# Template register map
Vendor: VendorName Co.Ltd; Series: SeriesName; File version: 1.2
CPU: CM0+ r0p1, little endian, no MPU, no FPU, 3 interrupt priority bits
Registers are 32-bit, read-write, no defined reset value unless marked. A register's access mark holds for its fields unless they carry their own. Offsets are from the block's base; lines under a group give offsets from that group; [hi:lo] are bit positions; {n}, {i} and the like mark numbered series; 'fields as' and 'values as' point back to an identical list; <NAME> marks a mode.

## Memory map
0x40000400 GTIM size 0x334 — General Timer
0x40002C00 WWDT size 0xC
0x40003000 IWDT size 0x28
0x40004400 UART2 size 0x38
0x40005400 I2C size 0x2C
0x40010000 SYSCTRL size 0x78 — System Ctrl
0x40012400 ADC size 0x8C
0x40012A00 VC1 size 0x10
0x40012A10 VC2 size 0x10
0x40012A80 LVD size 0xC
0x40012C00 ATIM size 0x5C
0x40013000 SPI size 0x1C
0x40013800 UART1 size 0x38
0x40014800 BTIM1 size 0x20 — Base Timer 1
0x40014900 BTIM2 size 0x20 — Base Timer 2
0x40014A00 BTIM3 size 0x20 — Base Timer 3
0x40014C00 AWT size 0x20
0x40022000 FLASH size 0x2C
0x40022400 RAM size 0x10
0x40023000 CRC size 0x10
0x48000000 GPIOA size 0x64
0x48000400 GPIOB size 0x64
0x48000800 GPIOC size 0x64

## Interrupts
0 WDT (IWDT, WWDT) — Watch Dog Timer Interrupt
1 LVD — Low Voltage Detect Interrupt
3 FLASHRAM (FLASH, RAM) — Flash/RAM Interrupt
4 RCC (SYSCTRL) — RCC Interupt
5 GPIOA — GPIOA Interrupt
6 GPIOB — GPIOB Interrupt
7 GPIOC — GPIOC Interrupt
12 ADC — ADC Interrupt
13 ATIM — Advanced Timer Interrupt
14 VC1 — Voltage Comparator 1 Interrupt
15 VC2 — Voltage Comparator 2 Interrupt
16 GTIM — General Timer Interrupt
20 BTIM1 — Base Timer1 Interrupt
21 BTIM2 — Base Timer2 Interrupt
22 BTIM3 — Base Timer3 Interrupt
23 I2C — I2C Interrupt
25 SPI — SPI Interrupt
27 UART1 — UART1 Interrupt
28 UART2 — UART2 Interrupt
30 AWT — Auto Wakeup Timer Interrupt

## ADC
Base 0x40012400
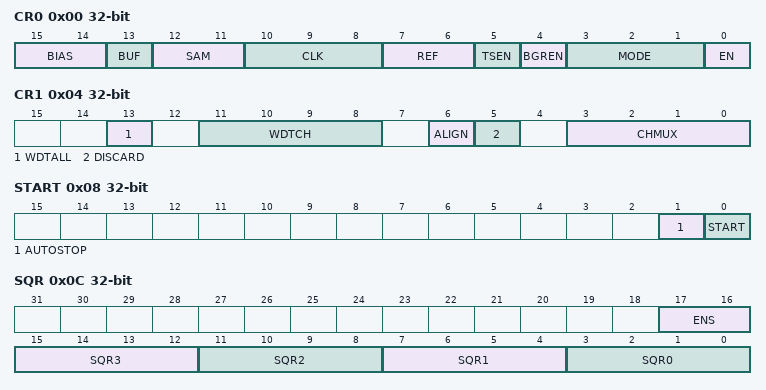
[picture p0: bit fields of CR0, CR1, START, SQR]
0x00 CR0 — Control register0
  [15:14] BIAS, [13] BUF, [12:11] SAM, [10:8] CLK, [7:6] REF, [5] TSEN, [4] BGREN, [3:1] MODE, [0] EN
0x04 CR1 — Control register1
  [13] WDTALL, [11:8] WDTCH, [6] ALIGN, [5] DISCARD, [3:0] CHMUX
0x08 START
  [1] AUTOSTOP, [0] START
0x0C SQR
  [17:16] ENS, [4n+3:4n] SQR{n} (n=0..3)
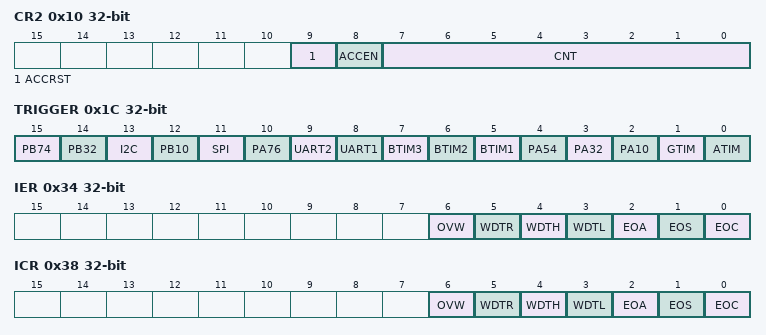
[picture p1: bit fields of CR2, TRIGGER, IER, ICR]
0x10 CR2 — Control register2
  [9] ACCRST, [8] ACCEN, [7:0] CNT
0x14 VTH
  [11:0] VTH
0x18 VTL
  [11:0] VTL
0x1C TRIGGER
  [15] PB74, [14] PB32, [13] I2C, [12] PB10, [11] SPI, [10] PA76, [9] UART2, [8] UART1, [7] BTIM3, [6] BTIM2, [5] BTIM1, [4] PA54, [3] PA32, [2] PA10, [1] GTIM, [0] ATIM
{0x20+4i} RESULT{i} ro (i=0..3)
  [15:0] RESULT
0x30 RESULTACC ro
  [23:0] RESULT
0x34 IER — Interrupt enable register
  [6] OVW, [5] WDTR, [4] WDTH, [3] WDTL, [2] EOA, [1] EOS, [0] EOC
0x38 ICR — Interrupt flag clear register
  [6] OVW, [5] WDTR, [4] WDTH, [3] WDTL, [2] EOA, [1] EOS, [0] EOC
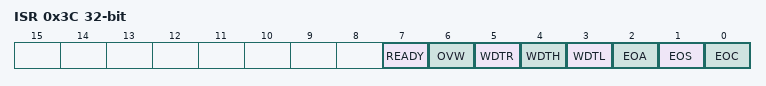
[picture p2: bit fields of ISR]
0x3C ISR ro — Interrupt status register
  [7] READY, [6] OVW, [5] WDTR, [4] WDTH, [3] WDTL, [2] EOA, [1] EOS, [0] EOC

## ATIM
Base 0x40012C00
0x00 ARR
  [15:0] ARR
0x04 CNT
  [15:0] CNT
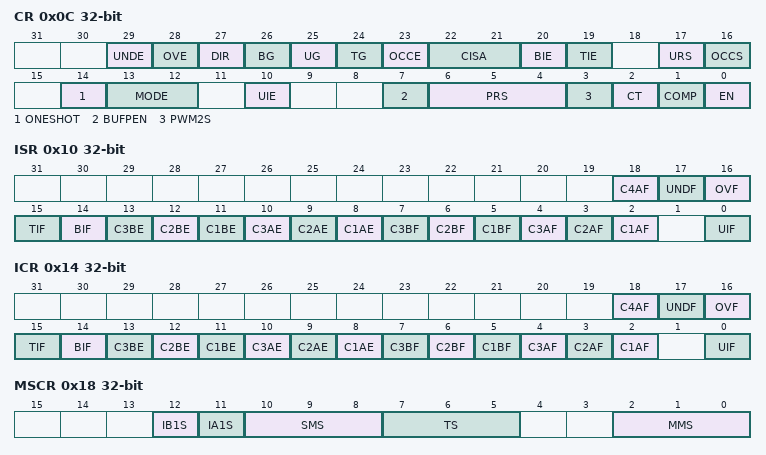
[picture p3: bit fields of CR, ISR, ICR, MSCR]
0x0C CR
  [29] UNDE
  [28] OVE
  [27] DIR
  [26] BG
  [25] UG
  [24] TG
  [23] OCCE
  [22:21] CISA
  [20] BIE
  [19] TIE
  [17] URS
  [16] OCCS
  [14] ONESHOT
  [13:12] MODE — Please keep 10/11
  [10] UIE
  [7] BUFPEN
  [6:4] PRS
  [3] PWM2S
  [2] CT
  [1] COMP
  [0] EN
0x10 ISR ro
  [18] C4AF, [17] UNDF, [16] OVF, [15] TIF, [14] BIF, [13] C3BE, [12] C2BE, [11] C1BE, [10] C3AE, [9] C2AE, [8] C1AE, [7] C3BF, [6] C2BF, [5] C1BF, [4] C3AF, [3] C2AF, [2] C1AF, [0] UIF
0x14 ICR
  fields as ISR
0x18 MSCR
  [12] IB1S, [11] IA1S, [10:8] SMS, [7:5] TS, [2:0] MMS
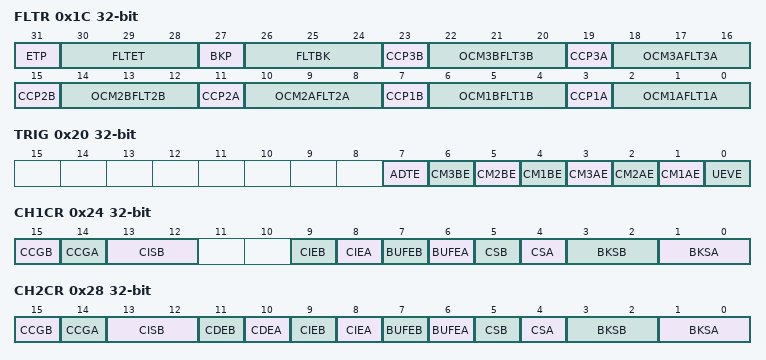
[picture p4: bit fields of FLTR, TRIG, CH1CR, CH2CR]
0x1C FLTR
  [31] ETP, [30:28] FLTET, [27] BKP, [26:24] FLTBK, [23] CCP3B, [22:20] OCM3BFLT3B, [19] CCP3A, [18:16] OCM3AFLT3A, [15] CCP2B, [14:12] OCM2BFLT2B, [11] CCP2A, [10:8] OCM2AFLT2A, [7] CCP1B, [6:4] OCM1BFLT1B, [3] CCP1A, [2:0] OCM1AFLT1A
0x20 TRIG
  [7] ADTE, [6] CM3BE, [5] CM2BE, [4] CM1BE, [3] CM3AE, [2] CM2AE, [1] CM1AE, [0] UEVE
0x24 CH1CR
  [15] CCGB, [14] CCGA, [13:12] CISB, [9] CIEB, [8] CIEA, [7] BUFEB, [6] BUFEA, [5] CSB, [4] CSA, [3:2] BKSB, [1:0] BKSA
0x28 CH2CR
  [15] CCGB, [14] CCGA, [13:12] CISB, [11] CDEB, [10] CDEA, [9] CIEB, [8] CIEA, [7] BUFEB, [6] BUFEA, [5] CSB, [4] CSA, [3:2] BKSB, [1:0] BKSA
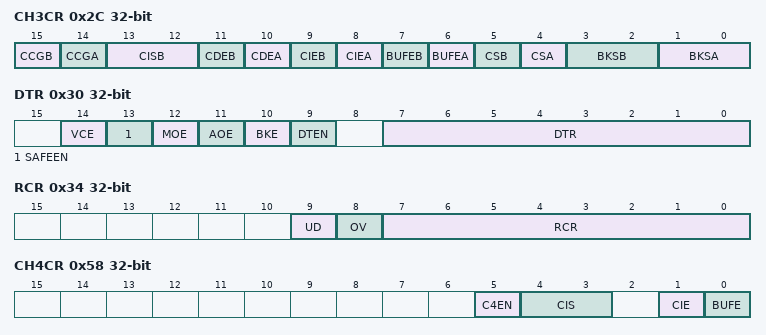
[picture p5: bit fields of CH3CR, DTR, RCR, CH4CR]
0x2C CH3CR
  fields as CH2CR
0x30 DTR
  [14] VCE, [13] SAFEEN, [12] MOE, [11] AOE, [10] BKE, [9] DTEN, [7:0] DTR
0x34 RCR
  [9] UD, [8] OV, [7:0] RCR
{0x34+8i} CH{i}CCRA (i=1..3)
  [15:0] CCR{i}A
{0x38+8i} CH{i}CCRB (i=1..3)
  [15:0] CCR{i}B
0x54 CH4CCR
  [15:0] CCR4
0x58 CH4CR
  [5] C4EN, [4:3] CIS, [1] CIE, [0] BUFE
